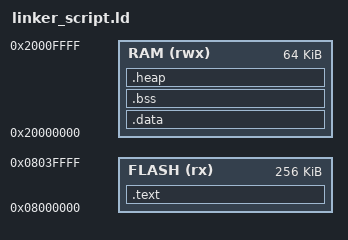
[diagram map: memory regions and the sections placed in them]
MEMORY
{
    FLASH (rx) : ORIGIN = 0x08000000, LENGTH = 256K
    RAM (rwx)  : ORIGIN = 0x20000000, LENGTH = 64K
}

_estack = 0x20010000;

SECTIONS
{
    .text :
    {
        . = ALIGN(4);
        KEEP(*(.isr_vector))
        . = ALIGN(4);
        *(.text)
        *(.text*)
        . = ALIGN(4);
        *(.rodata)
        *(.rodata*)
        . = ALIGN(4);
        _etext = .;
    } > FLASH

    .data : AT(_etext)
    {
        . = ALIGN(4);
        _sdata = .;
        *(.data)
        *(.data*)
        . = ALIGN(4);
        _edata = .;
    } > RAM

    .bss :
    {
        . = ALIGN(4);
        _sbss = .;
        *(.bss)
        *(.bss*)
        *(COMMON)
        . = ALIGN(4);
        _ebss = .;
    } > RAM

    .heap :
    {
        . = ALIGN(8);
        _heap_start = .;
        . = . + 0x200;
        . = ALIGN(8);
        _heap_end = 0x2000E000;
    } > RAM

    /DISCARD/ :
    {
        libc.a (*)
        libm.a (*)
        libgcc.a (*)
    }
}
